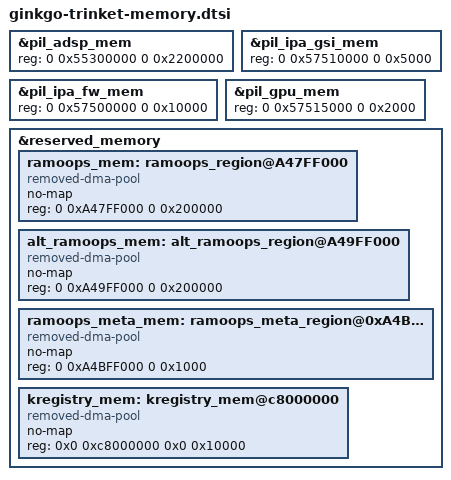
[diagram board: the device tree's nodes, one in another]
/* Copyright (c) 2020, The Linux Foundation. All rights reserved.
 *
 * This program is free software; you can redistribute it and/or modify
 * it under the terms of the GNU General Public License version 2 and
 * only version 2 as published by the Free Software Foundation.
 *
 * This program is distributed in the hope that it will be useful,
 * but WITHOUT ANY WARRANTY; without even the implied warranty of
 * MERCHANTABILITY or FITNESS FOR A PARTICULAR PURPOSE.  See the
 * GNU General Public License for more details.
 */

&pil_adsp_mem {
    reg = <0 0x55300000 0 0x2200000>;
};

&pil_ipa_fw_mem {
    reg = <0 0x57500000 0 0x10000>;
};

&pil_ipa_gsi_mem {
    reg = <0 0x57510000 0 0x5000>;
};

&pil_gpu_mem {
    reg = <0 0x57515000 0 0x2000>;
};

&reserved_memory {
	ramoops_mem: ramoops_region@A47FF000 {
		compatible = "removed-dma-pool";
		no-map;
		reg = <0 0xA47FF000 0 0x200000>;
	};

	alt_ramoops_mem: alt_ramoops_region@A49FF000 {
		compatible = "removed-dma-pool";
		no-map;
		reg = <0 0xA49FF000 0 0x200000>;
	};

	ramoops_meta_mem: ramoops_meta_region@0xA4BFF000 {
		compatible = "removed-dma-pool";
		no-map;
		reg = <0 0xA4BFF000 0 0x1000>;
	};

	kregistry_mem: kregistry_mem@c8000000 {
		compatible = "removed-dma-pool";
		no-map;
		reg = <0x0 0xc8000000 0x0 0x10000>;
	};
};
